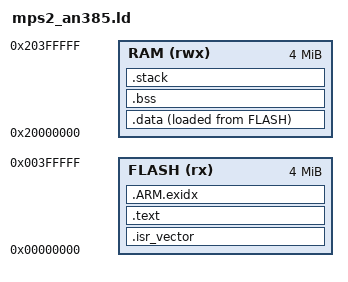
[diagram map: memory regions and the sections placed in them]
/* QEMU mps2-an385: Cortex-M3 with 4 MB of SSRAM at 0 for code and 4 MB at
 * 0x20000000 for data. The runner's test vectors need the room; the size
 * report is taken from the linker map, not from these lengths. */
MEMORY
{
    FLASH (rx)  : ORIGIN = 0x00000000, LENGTH = 4M
    RAM   (rwx) : ORIGIN = 0x20000000, LENGTH = 4M
}

ENTRY(Reset_Handler)

_stack_size = 16K;

SECTIONS
{
    .isr_vector : ALIGN(4)
    {
        KEEP(*(.isr_vector))
    } > FLASH

    .text : ALIGN(4)
    {
        *(.text .text.*)
        *(.rodata .rodata.*)
        KEEP(*(.init))
        KEEP(*(.fini))
        . = ALIGN(4);
        __init_array_start = .;
        KEEP(*(SORT(.init_array.*)))
        KEEP(*(.init_array))
        __init_array_end = .;
    } > FLASH

    .ARM.exidx : ALIGN(4)
    {
        *(.ARM.exidx* .gnu.linkonce.armexidx.*)
    } > FLASH

    _sidata = LOADADDR(.data);

    .data : ALIGN(4)
    {
        _sdata = .;
        *(.data .data.*)
        . = ALIGN(4);
        _edata = .;
    } > RAM AT > FLASH

    .bss (NOLOAD) : ALIGN(4)
    {
        _sbss = .;
        *(.bss .bss.*)
        *(COMMON)
        . = ALIGN(4);
        _ebss = .;
    } > RAM

    .stack (NOLOAD) : ALIGN(8)
    {
        . += _stack_size;
        _estack = .;
    } > RAM
}
